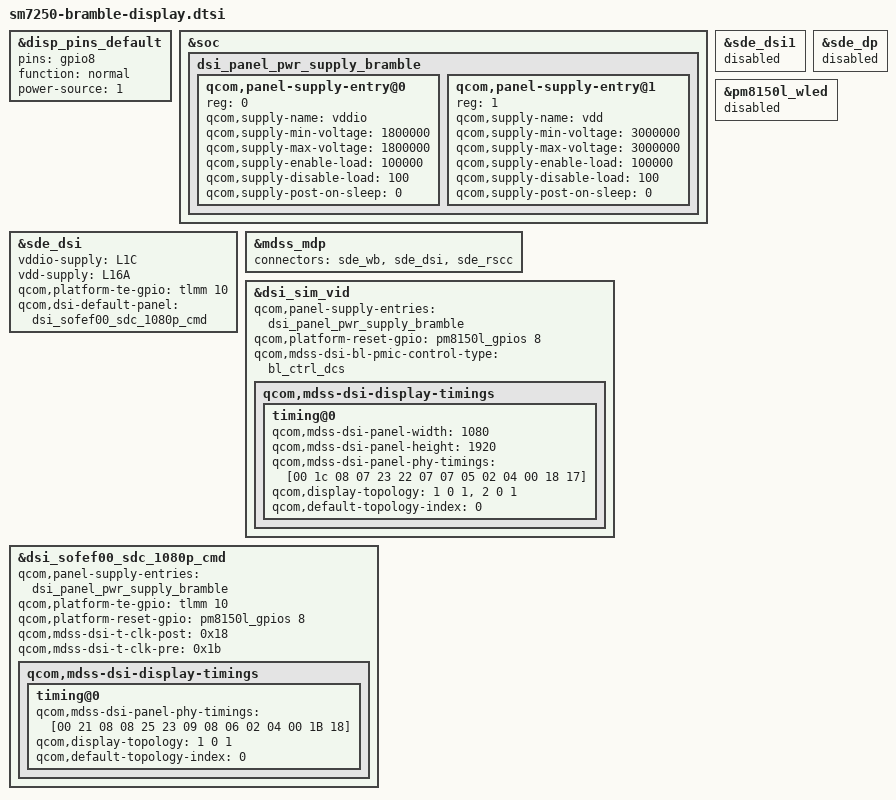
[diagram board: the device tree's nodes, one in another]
#include "dsi-panel-sofef00-1080p-cmd.dtsi"

&disp_pins_default {
	pins = "gpio8";
	function = "normal";
	power-source = <1>;
};

&soc {
	dsi_panel_pwr_supply_bramble: dsi_panel_pwr_supply_bramble {
		#address-cells = <1>;
		#size-cells = <0>;

		qcom,panel-supply-entry@0 {
			reg = <0>;
			qcom,supply-name = "vddio";
			qcom,supply-min-voltage = <1800000>;
			qcom,supply-max-voltage = <1800000>;
			qcom,supply-enable-load = <100000>;
			qcom,supply-disable-load = <100>;
			qcom,supply-post-on-sleep = <0>;
		};

		qcom,panel-supply-entry@1 {
			reg = <1>;
			qcom,supply-name = "vdd";
			qcom,supply-min-voltage = <3000000>;
			qcom,supply-max-voltage = <3000000>;
			qcom,supply-enable-load = <100000>;
			qcom,supply-disable-load = <100>;
			qcom,supply-post-on-sleep = <0>;
		};
	};
};

&sde_dsi {
	vddio-supply = <&L1C>;
	vdd-supply = <&L16A>;
	qcom,platform-te-gpio = <&tlmm 10 0>;
	qcom,dsi-default-panel = <&dsi_sofef00_sdc_1080p_cmd>;
};

&sde_dsi1 {
    status = "disabled";
};

&sde_dp {
	status = "disabled";
};


&mdss_mdp {
	connectors = <&sde_wb &sde_dsi &sde_rscc>;
};

&pm8150l_wled {
	status = "disabled";
};

&dsi_sim_vid {
	qcom,panel-supply-entries = <&dsi_panel_pwr_supply_bramble>;
	qcom,platform-reset-gpio = <&pm8150l_gpios 8 0>;
	qcom,mdss-dsi-bl-pmic-control-type = "bl_ctrl_dcs";
	qcom,mdss-dsi-display-timings {
		timing@0 {
			qcom,mdss-dsi-panel-width = <1080>;
			qcom,mdss-dsi-panel-height = <1920>;
			qcom,mdss-dsi-panel-phy-timings = [00 1c 08 07 23 22 07
				07 05 02 04 00 18 17];
			qcom,display-topology = <1 0 1>,
						<2 0 1>;
			qcom,default-topology-index = <0>;
		};
	};
};

&dsi_sofef00_sdc_1080p_cmd {
	qcom,panel-supply-entries = <&dsi_panel_pwr_supply_bramble>;
	qcom,platform-te-gpio = <&tlmm 10 0>;
	qcom,platform-reset-gpio = <&pm8150l_gpios 8 0>;
	qcom,mdss-dsi-t-clk-post = <0x18>;
	qcom,mdss-dsi-t-clk-pre = <0x1b>;
	qcom,mdss-dsi-display-timings {
		timing@0 {
			qcom,mdss-dsi-panel-phy-timings = [00 21 08 08 25 23 09
				08 06 02 04 00 1B 18];
			qcom,display-topology = <1 0 1>;
			qcom,default-topology-index = <0>;
		};
	};
};
